# K1921VK028 register map
Vendor: NIIET; Series: K1921VKx; File version: 2.17
CPU: CM4 r0p1, little endian, MPU, FPU, 4 interrupt priority bits
Registers are 32-bit, read-write, reset 0x0 unless marked. A register's access mark holds for its fields unless they carry their own. Offsets are from the block's base; [hi:lo] are bit positions; lines under a group give offsets from that group; {n}, {i} and the like mark numbered series; 'fields as' and 'values as' point back to an identical list.

## ADC — ADC control registers
Base 0x400B1000
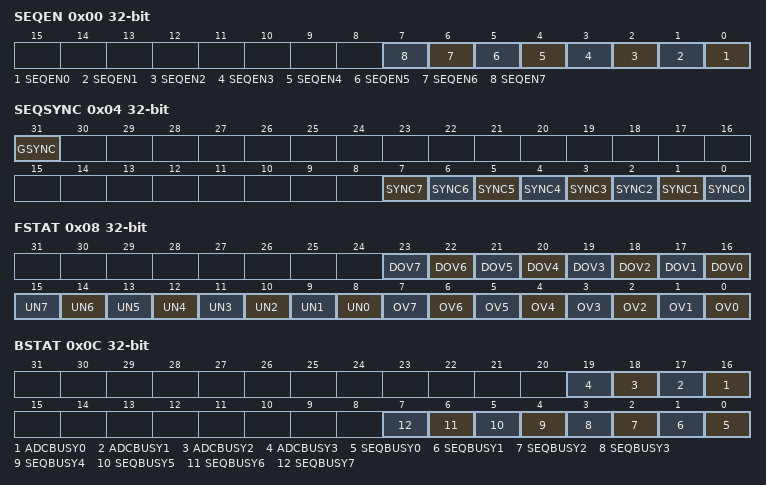
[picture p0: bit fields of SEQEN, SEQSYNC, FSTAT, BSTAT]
0x00 SEQEN — Enable sequencer register
  [n] SEQEN{n} (n=0..7) — Enable sequencer {n}
0x04 SEQSYNC — Sequencer sync register
  [31] GSYNC wo — Sync all sequencers
  [n] SYNC{n} (n=0..7) — Enable sequencer {n} software sync
0x08 FSTAT — FIFO overflow status register
  [n+16] DOV{n} (n=0..7) — Sequencer {n} FIFO DMA request overflow
  [n+8] UN{n} (n=0..7) — Sequencer {n} FIFO underflow
  [n] OV{n} (n=0..7) — Sequencer {n} FIFO overflow
0x0C BSTAT ro — Busy status register
  [n+16] ADCBUSY{n} (n=0..3) — ADC module {n} conversion busy
  [n] SEQBUSY{n} (n=0..7) — Sequencer {n} busy
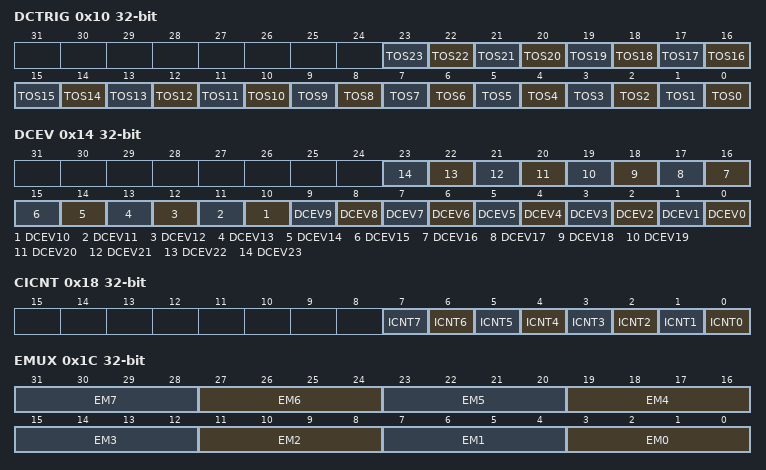
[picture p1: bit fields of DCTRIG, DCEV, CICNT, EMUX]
0x10 DCTRIG wo — Digital comparator output trigger status register
  [n] TOS{n} (n=0..23) — DC {n} output trigger status
0x14 DCEV wo — Digital comparator compare event status register
  [n] DCEV{n} (n=0..23) — Digital compare event {n}
0x18 CICNT — Interrupt counter clear control
  [n] ICNT{n} (n=0..7) — Clear interrupt counter on sequencer {n} start
0x1C EMUX — Sequencer start event selection register
  [all] fields
    0=SwReq (software request by GSYNC bit); 1=GPIOABCD (GPIOA or GPIOB or GPIOC or GPIOD interrupt); 2=GPIOEFGH (GPIOE or GPIOF or GPIOG or GPIOH interrupt); 3=GPIOJKLM (GPIOJ or GPIOK or GPIOL or GPIOM interrupt); {v}=TMR{v-5} (Timer {v-5} request) (v=5..8); 9=PWM012A (PWM0,1,2 A channel request); 10=PWM012B (PWM0,1,2 B channel request); 11=PWM345A (PWM3,4,5 A channel request); 12=PWM345B (PWM3,4,5 B channel request); 13=PWM6789A (PWM6,7,8,9 A channel request); 14=PWM6789B (PWM6,7,8,9 B channel request); 15=Cycle mode
  [4n+3:4n] EM{n} (n=0..7) — Select start event for sequencer {n}
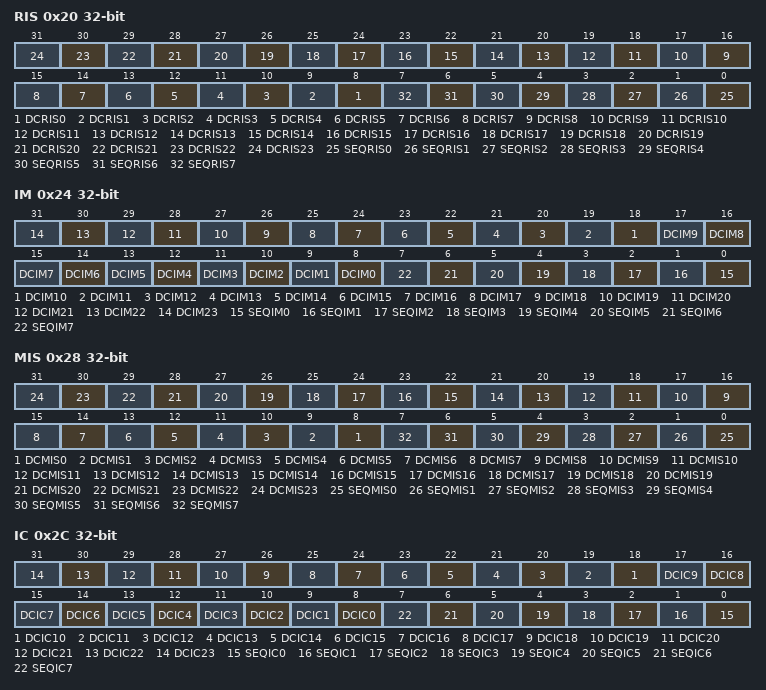
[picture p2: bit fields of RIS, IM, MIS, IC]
0x20 RIS ro — Raw interrupt status register
  [n+8] DCRIS{n} (n=0..23) — Raw interrupt status of Digital Comparator {n}
  [n] SEQRIS{n} (n=0..7) — Sequencer {n} raw interrupt status
0x24 IM — Interrupt mask register
  [n+8] DCIM{n} (n=0..23) — Interrupt mask of Digital Comparator {n}
  [n] SEQIM{n} (n=0..7) — Sequencer {n} interrupt mask
0x28 MIS ro — Masked interrupt status and clear register
  [n+8] DCMIS{n} (n=0..23) — DC {n} masked interrupt status
  [n] SEQMIS{n} (n=0..7) — Sequencer {n} masked interrupt status
0x2C IC wo — Interrupt clear register
  [n+8] DCIC{n} (n=0..23) — DC {n} interrupt status clear
  [n] SEQIC{n} (n=0..7) — Sequencer {n} interrupt status clear
{0x40+0x3C*i} SEQ[{i}] (i=0..7) group
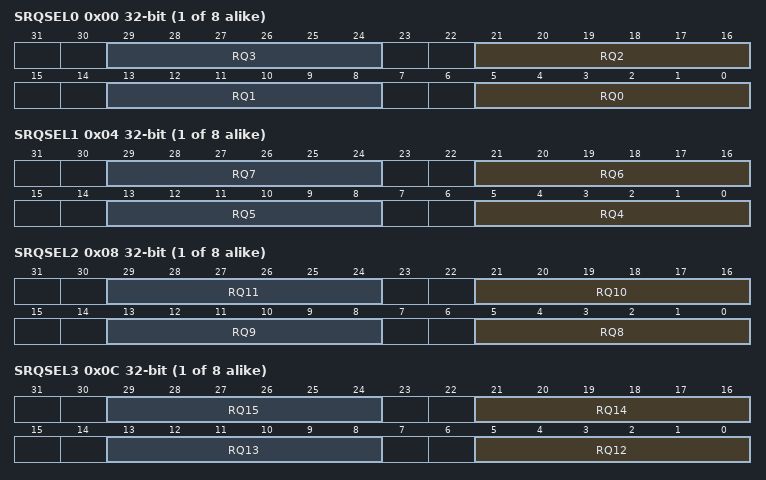
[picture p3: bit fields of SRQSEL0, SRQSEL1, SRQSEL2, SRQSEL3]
  0x00 SRQSEL0 — Sequencer request ADC channels selection register 0
    [8n+5:8n] RQ{n} (n=0..3) — Select ADC channel for request {n}
  0x04 SRQSEL1 — Sequencer request ADC channels selection register 1
    [8n-27:8n-32] RQ{n} (n=4..7) — Select ADC channel for request {n}
  0x08 SRQSEL2 — Sequencer request ADC channels selection register 2
    [8n-59:8n-64] RQ{n} (n=8..11) — Select ADC channel for request {n}
  0x0C SRQSEL3 — Sequencer request ADC channels selection register 3
    [8n-91:8n-96] RQ{n} (n=12..15) — Select ADC channel for request {n}
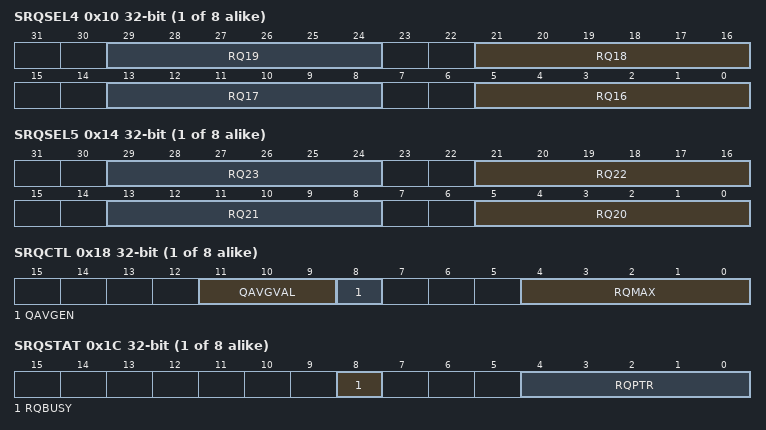
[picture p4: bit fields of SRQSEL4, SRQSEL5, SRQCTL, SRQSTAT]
  0x10 SRQSEL4 — Sequencer request ADC channels selection register 4
    [8n-123:8n-128] RQ{n} (n=16..19) — Select ADC channel for request {n}
  0x14 SRQSEL5 — Sequencer request ADC channels selection register 5
    [8n-155:8n-160] RQ{n} (n=20..23) — Select ADC channel for request {n}
  0x18 SRQCTL — Sequencer request control register
    [11:9] QAVGVAL — Queue average value
      0=Disable (Average disabled); 1=Average2 (Average with 2 measures); 2=Average4 (Average with 4 measures); 3=Average8 (Average with 8 measures); 4=Average16 (Average with 16 measures); 5=Average32 (Average with 32 measures); 6=Average64 (Average with 64 measures)
    [8] QAVGEN — Queue avearage (scanning) enable
    [4:0] RQMAX — Request queue max depth
  0x1C SRQSTAT — Sequencer request status register
    [8] RQBUSY ro — Active request status
    [4:0] RQPTR ro — Pointer to queue current request
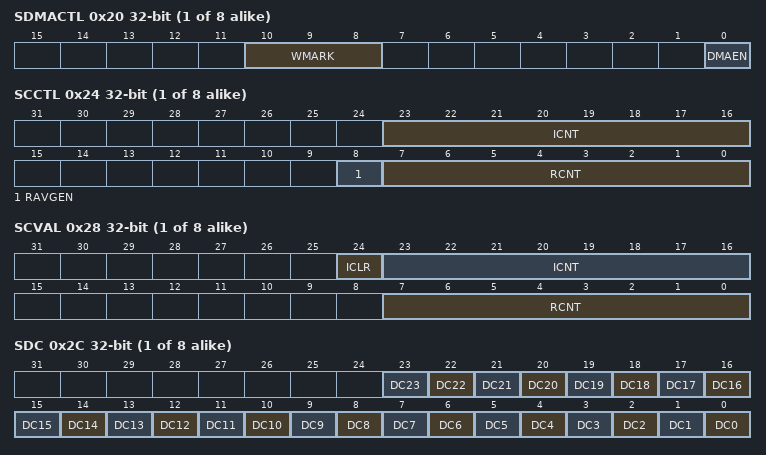
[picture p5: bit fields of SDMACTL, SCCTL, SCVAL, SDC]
  0x20 SDMACTL — Sequencer DMA control register
    [10:8] WMARK — FIFO load threshold for DMA request generation
      1=Level1 (1 measure for dma request); 2=Level2 (2 measures for dma request); 3=Level4 (4 measures for dma request); 4=Level8 (8 measures for dma request); 5=Level16 (16 measures for dma request); 6=Level32 (32 measures for dma request)
    [0] DMAEN — Enable DMA use
  0x24 SCCTL — Sequencer ADC interrupt and restart counter control register
    [23:16] ICNT — Number of ADC restarts for interrupt generation
    [8] RAVGEN — Average of ADC restarts enable
    [7:0] RCNT — Current number of ADC restarts by sequencer
  0x28 SCVAL wo — Sequencer ADC interrupt and restart counter current value register
    [24] ICLR — Clear interrupt counter
    [23:16] ICNT ro — Current number of ADC restarts for interrupt generation
    [7:0] RCNT ro — Current number of ADC restarts by sequencer
  0x2C SDC — Sequencer digital comparator selection register
    [n] DC{n} (n=0..23) — Enable DC {n}
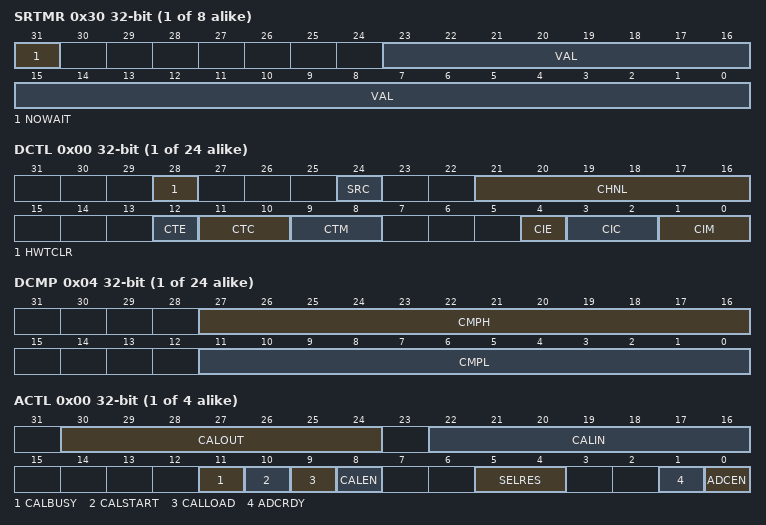
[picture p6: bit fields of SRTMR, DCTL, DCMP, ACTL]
  0x30 SRTMR — Sequencer ADC restart timer register
    [31] NOWAIT — Timer update with no waiting the end of current seq task
    [23:0] VAL — Sequencer ADC restart timer value
  0x34 SFLOAD ro — Sequencer FIFO load status register
    [5:0] VAL — Sequencer FIFO current load value
  0x38 SFIFO ro — Sequencer FIFO register
    [11:0] DATA — AD conversion value
{0x400+0xC*i} DC[{i}] (i=0..23) group
  0x00 DCTL — Digital comparator control register
    [28] HWTCLR — Hardware output trigger clear
    [24] SRC — Select data source for comparation: ADC module (0) or sequencer(1)
    [21:16] CHNL — ADC channel selection
    [12] CTE — Enable DC output trigger
    [11:10] CTC — DC output trigger compare conditions
      0=Low (result lower or equal COMP0); 1=Window (result between COMP0 and COMP1 or equal any of them); 2=High (result higher or equal COMP1)
    [9:8] CTM — DC output trigger mode
      0=multiple trigger mode; 1=single trigger mode; 2=MultipleHyst (multiple trigger mode with hysteresis); 3=SingleHyst (single trigger mode with hysteresis)
    [4] CIE — Enable DC interrupt generation
    [3:2] CIC — DC interrupt generation compare conditions
      values as CTC
    [1:0] CIM — DC interrupt generation mode
      values as CTM
  0x04 DCMP — Digital comparator range register
    [27:16] CMPH — High threshold compare value
    [11:0] CMPL — Low threshold compare value
  0x08 DDATA ro — Digital comparator last compared data register
    [11:0] VAL — Value of last compared AD conversion result
{0x540+4i} ACTL[{i}] (i=0..3) group
  0x00 ACTL — ADC module control register
    [30:24] CALOUT ro — ADC calibration output value
    [22:16] CALIN — ADC calibration input value
    [11] CALBUSY ro — Enable ADC internal calibration
    [10] CALSTART
    [9] CALLOAD
    [8] CALEN
    [5:4] SELRES — ADC resolution select
      0=6 bit mode; 1=8 bit mode; 2=10 bit mode; 3=12 bit mode
    [1] ADCRDY ro — ADC ready for conversions
    [0] ADCEN — Enable ADC module
{0x580+4i} CHCTL[{i}] (i=0..47) group
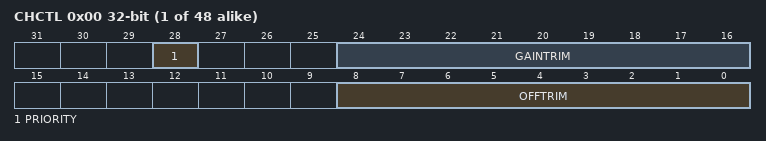
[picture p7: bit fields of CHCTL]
  0x00 CHCTL — ADC channel control register
    [28] PRIORITY — ADC channel priority level
    [24:16] GAINTRIM — ADC channel gain trimm value
    [8:0] OFFTRIM — ADC channel offset trimm value
